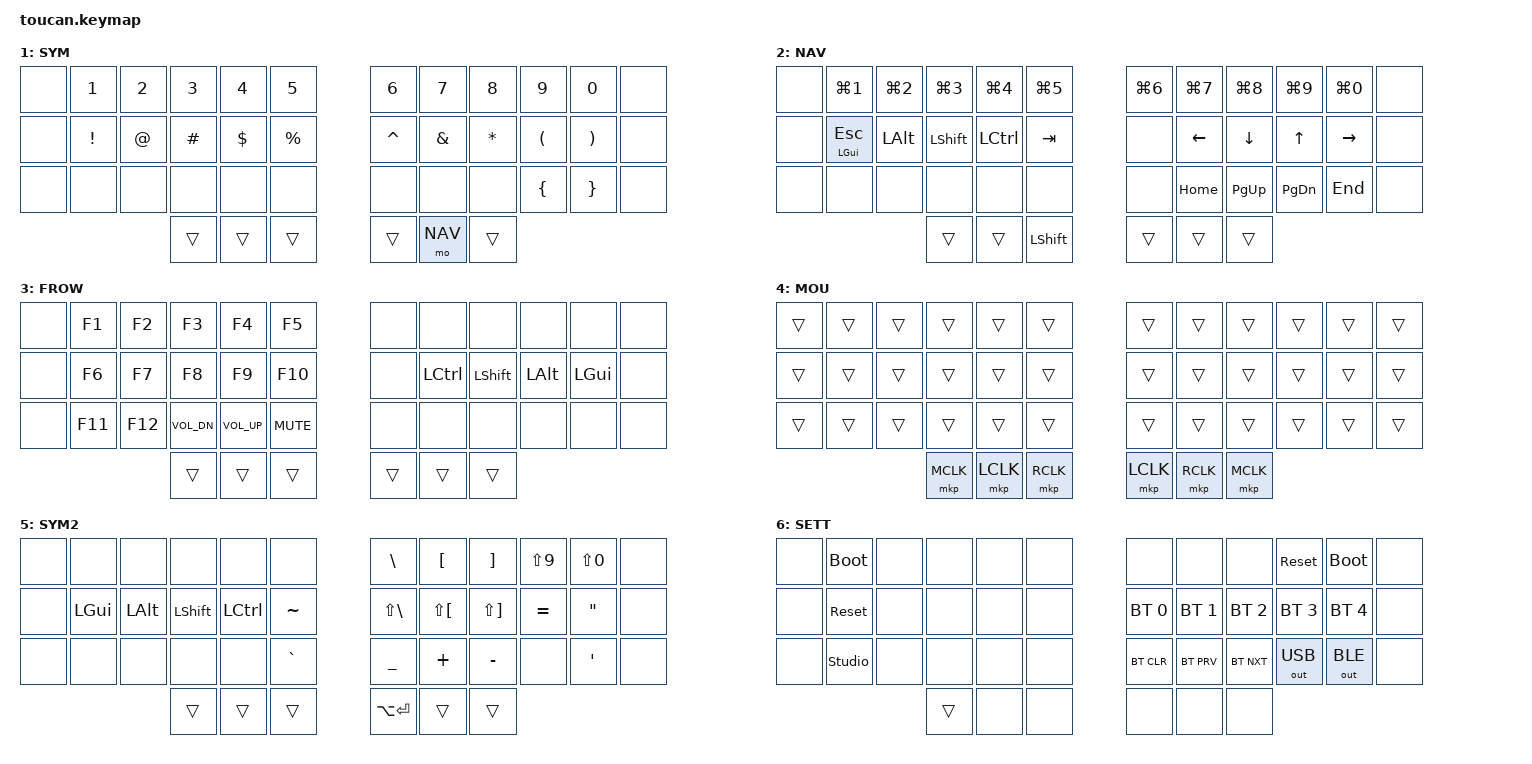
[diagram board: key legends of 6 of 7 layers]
#include <behaviors.dtsi>
#include <dt-bindings/zmk/keys.h>
#include <dt-bindings/zmk/bt.h>
#include <dt-bindings/zmk/outputs.h>
#include <dt-bindings/zmk/pointing.h>

// Home row mods macro
#define HRML(k1,k2,k3,k4) &mt LGUI k1  &mt LALT k2  &mt LSHIFT k3  &mt LCTRL k4
#define HRMR(k1,k2,k3,k4) &mt RCTRL k1  &mt RSHIFT k2  &mt RALT k3  &mt RGUI k4

// The Toucan matrix is 12 columns wide, but this board only has the inner 5 per
// side (36 keys), so the outer column of every row is &none.

// Layer definitions
// NOTE: MOUSE must stay at 4 - the trackpad's is_touching_processor in
// boards/shields/toucan/toucan.dtsi activates layer 4 while touched, and the
// scroller there is active on layers 1 and 2 (SYM / NAV).
#define BASE     0
#define SYM      1
#define NAV      2
#define FNC      3
#define MOUSE    4
#define SYM2     5
#define SETTINGS 6
// -----------------

&sk {
    // don't release mods on other mods presses
    ignore-modifiers;
};

&mt {
    flavor = "balanced";
    tapping-term-ms = <150>;
    quick-tap-ms = <150>;
};

&lt {
    flavor = "tap-preferred";
    tapping-term-ms = <150>;
    quick-tap-ms = <200>;
};

/ {
    // FNC is on the outer right thumb now; uncomment to also get it from SYM + NAV
    /*
    conditional_layers {
        compatible = "zmk,conditional-layers";
        tri_layer {
            if-layers = <SYM NAV>;
            then-layer = <FNC>;
        };
    };
    */

    keymap {
        compatible = "zmk,keymap";

        // Base alpha layer
        base {
            display-name = "BASE";
            bindings = <
            &none     &kp Q &kp W &kp E &kp R &kp T                 &kp Y &kp U &kp I     &kp O   &kp P     &none
            &none     HRML(A,   S,    D,    F)    &kp G             &kp H HRMR(J,   K,        L,      SEMICOLON)    &none
            &none     &kp Z &kp X &kp C &kp V &kp B                 &kp N &kp M &kp COMMA &kp DOT &kp SLASH &none
                        &mo SETTINGS &mo SYM &lt SYM2 SPACE         &kp ENTER &lt NAV BACKSPACE &mo FNC
            >;
        };

        // Numbers and high frequency symbols
        sym {
            display-name = "SYM";
            bindings = <
            &none  &kp N1          &kp N2 &kp N3   &kp N4     &kp N5          &kp N6    &kp N7        &kp N8       &kp N9               &kp N0                &none
            &none  &kp EXCLAMATION &kp AT &kp HASH &kp DOLLAR &kp PERCENT     &kp CARET &kp AMPERSAND &kp ASTERISK &kp LEFT_PARENTHESIS &kp RIGHT_PARENTHESIS &none
            &none  &none           &none  &none    &none      &none           &none     &none         &none        &kp LEFT_BRACE       &kp RIGHT_BRACE       &none
                                          &trans   &trans     &trans          &trans    &mo NAV       &trans
            >;
        };

        // Main modifiers and arrow keys
        nav {
            display-name = "NAV";
            bindings = <
            &none  &kp LG(N1)   &kp LG(N2) &kp LG(N3) &kp LG(N4) &kp LG(N5)     &kp LG(N6) &kp LG(N7) &kp LG(N8)  &kp LG(N9)    &kp LG(N0) &none
            &none  &mt LGUI ESC &kp LALT   &kp LSHIFT &kp LCTRL  &kp TAB        &none      &kp LEFT   &kp DOWN    &kp UP        &kp RIGHT  &none
            &none  &none        &none      &none      &none      &none          &none      &kp HOME   &kp PAGE_UP &kp PAGE_DOWN &kp END    &none
                                           &trans     &trans     &kp LSHIFT     &trans     &trans     &trans
            >;
        };

        // Function keys with modifiers (hold outer right thumb)
        fnc {
            display-name = "FROW";
            bindings = <
            &none  &kp F1  &kp F2  &kp F3       &kp F4       &kp F5         &none &none     &none      &none    &none    &none
            &none  &kp F6  &kp F7  &kp F8       &kp F9       &kp F10        &none &kp LCTRL &kp LSHIFT &kp LALT &kp LGUI &none
            &none  &kp F11 &kp F12 &kp K_VOL_DN &kp K_VOL_UP &kp C_MUTE     &none &none     &none      &none    &none    &none
                                   &trans       &trans       &trans         &trans &trans   &trans
            >;
        };

        // Active while touching the trackpad
        mouse {
            display-name = "MOU";
            bindings = <
            &trans &trans &trans &trans &trans &trans           &trans &trans &trans &trans &trans &trans
            &trans &trans &trans &trans &trans &trans           &trans &trans &trans &trans &trans &trans
            &trans &trans &trans &trans &trans &trans           &trans &trans &trans &trans &trans &trans
                            &mkp MCLK &mkp LCLK &mkp RCLK           &mkp LCLK &mkp RCLK &mkp MCLK
            >;
        };

        // Low frequency symbols
        sym2 {
            display-name = "SYM2";
            bindings = <
            &none  &none    &none    &none      &none     &none           &kp BACKSLASH     &kp LEFT_BRACKET     &kp RIGHT_BRACKET     &kp LS(N9) &kp LS(N0)        &none
            &none  &kp LGUI &kp LALT &kp LSHIFT &kp LCTRL &kp TILDE       &kp LS(BACKSLASH) &kp LS(LEFT_BRACKET) &kp LS(RIGHT_BRACKET) &kp EQUAL  &kp DOUBLE_QUOTES &none
            &none  &none    &none    &none      &none     &kp GRAVE       &kp UNDERSCORE    &kp PLUS             &kp MINUS             &none      &kp SINGLE_QUOTE  &none
                                     &trans     &trans    &trans          &kp LA(ENTER)     &trans               &trans
            >;
        };

        // Keyboard settings: hold the outer left thumb.
        // Right home row selects BT profile 0-4, bottom row clears/cycles/switches output.
        // Bootloader/reset are per-half, so each side has its own.
        settings {
            display-name = "SETT";
            bindings = <
            &none &bootloader    &none &none &none &none     &none        &none        &none        &sys_reset   &bootloader  &none
            &none &sys_reset     &none &none &none &none     &bt BT_SEL 0 &bt BT_SEL 1 &bt BT_SEL 2 &bt BT_SEL 3 &bt BT_SEL 4 &none
            &none &studio_unlock &none &none &none &none     &bt BT_CLR   &bt BT_PRV   &bt BT_NXT   &out OUT_USB &out OUT_BLE &none
                                 &trans &none &none          &none &none &none
            >;
        };

        extra_1 {
            status = "reserved";
        };

        extra_2 {
            status = "reserved";
        };
    };
};
